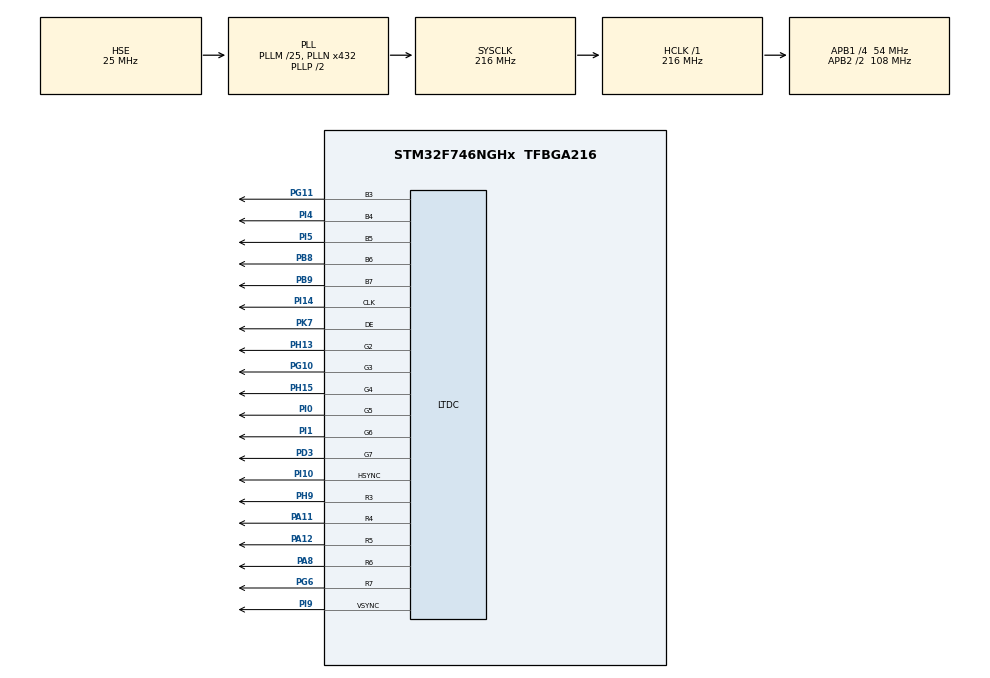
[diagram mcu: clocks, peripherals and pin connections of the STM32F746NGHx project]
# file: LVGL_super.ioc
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CORTEX_M7.default_mode_Activation=1
Mcu.Family=STM32F7
Mcu.Name=STM32F746NGHx
Mcu.Package=TFBGA216
NVIC.DMA2D_IRQn=true\:0\:0\:false\:false\:true\:true\:true\:true
NVIC.PriorityGroup=NVIC_PRIORITYGROUP_4
PA11.GPIO_Speed=GPIO_SPEED_FREQ_VERY_HIGH
PA11.Mode=RGB565
PA11.Signal=LTDC_R4
PA12.GPIO_Speed=GPIO_SPEED_FREQ_VERY_HIGH
PA12.Mode=RGB565
PA12.Signal=LTDC_R5
PA13.Mode=Serial_Wire
PA13.Signal=SYS_JTMS-SWDIO
PA14.Mode=Serial_Wire
PA14.Signal=SYS_JTCK-SWCLK
PA8.GPIO_Speed=GPIO_SPEED_FREQ_VERY_HIGH
PA8.Mode=RGB565
PA8.Signal=LTDC_R6
PB8.GPIO_Speed=GPIO_SPEED_FREQ_VERY_HIGH
PB8.Mode=RGB565
PB8.Signal=LTDC_B6
PB9.GPIO_Speed=GPIO_SPEED_FREQ_VERY_HIGH
PB9.Mode=RGB565
PB9.Signal=LTDC_B7
PD3.GPIO_Speed=GPIO_SPEED_FREQ_VERY_HIGH
PD3.Mode=RGB565
PD3.Signal=LTDC_G7
PG10.GPIO_Speed=GPIO_SPEED_FREQ_VERY_HIGH
PG10.Mode=RGB565
PG10.Signal=LTDC_G3
PG11.GPIO_Speed=GPIO_SPEED_FREQ_VERY_HIGH
PG11.Mode=RGB565
PG11.Signal=LTDC_B3
PG6.GPIO_Speed=GPIO_SPEED_FREQ_VERY_HIGH
PG6.Mode=RGB565
PG6.Signal=LTDC_R7
PH0/OSC_IN.Mode=HSE-External-Oscillator
PH0/OSC_IN.Signal=RCC_OSC_IN
PH1/OSC_OUT.Mode=HSE-External-Oscillator
PH1/OSC_OUT.Signal=RCC_OSC_OUT
PH13.GPIO_Speed=GPIO_SPEED_FREQ_VERY_HIGH
PH13.Mode=RGB565
PH13.Signal=LTDC_G2
PH15.GPIO_Speed=GPIO_SPEED_FREQ_VERY_HIGH
PH15.Mode=RGB565
PH15.Signal=LTDC_G4
PH9.GPIO_Speed=GPIO_SPEED_FREQ_VERY_HIGH
PH9.Mode=RGB565
PH9.Signal=LTDC_R3
PI0.GPIO_Speed=GPIO_SPEED_FREQ_VERY_HIGH
PI0.Mode=RGB565
PI0.Signal=LTDC_G5
PI1.GPIO_Speed=GPIO_SPEED_FREQ_VERY_HIGH
PI1.Mode=RGB565
PI1.Signal=LTDC_G6
PI10.GPIO_Speed=GPIO_SPEED_FREQ_VERY_HIGH
PI10.Mode=RGB565
PI10.Signal=LTDC_HSYNC
PI14.GPIO_Speed=GPIO_SPEED_FREQ_VERY_HIGH
PI14.Mode=RGB565
PI14.Signal=LTDC_CLK
PI4.GPIO_Speed=GPIO_SPEED_FREQ_VERY_HIGH
PI4.Mode=RGB565
PI4.Signal=LTDC_B4
PI5.GPIO_Speed=GPIO_SPEED_FREQ_VERY_HIGH
PI5.Mode=RGB565
PI5.Signal=LTDC_B5
PI9.GPIO_Speed=GPIO_SPEED_FREQ_VERY_HIGH
PI9.Mode=RGB565
PI9.Signal=LTDC_VSYNC
PK7.GPIO_Speed=GPIO_SPEED_FREQ_VERY_HIGH
PK7.Mode=RGB565
PK7.Signal=LTDC_DE
ProjectManager.HeapSize=0x200
ProjectManager.StackSize=0x400
ProjectManager.TargetToolchain=STM32CubeIDE
RCC.AHBFreq_Value=216000000
RCC.APB1CLKDivider=RCC_HCLK_DIV4
RCC.APB1Freq_Value=54000000
RCC.APB1TimFreq_Value=108000000
RCC.APB2CLKDivider=RCC_HCLK_DIV2
RCC.APB2Freq_Value=108000000
RCC.APB2TimFreq_Value=216000000
RCC.CortexFreq_Value=216000000
RCC.HCLKFreq_Value=216000000
RCC.HSE_VALUE=25000000
RCC.HSI_VALUE=16000000
RCC.LSE_VALUE=32768
RCC.PLLM=25
RCC.PLLN=432
RCC.PLLSAIN=180
RCC.PLLSourceVirtual=RCC_PLLSOURCE_HSE
RCC.SYSCLKFreq_VALUE=216000000
RCC.SYSCLKSource=RCC_SYSCLKSOURCE_PLLCLK
RCC.USBFreq_Value=216000000
RCC.VCOOutputFreq_Value=432000000
VP_DMA2D_VS_DMA2D.Mode=DMA2D_Activate
board=custom

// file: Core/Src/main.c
/* USER CODE BEGIN Header */
/**
  ******************************************************************************
  * @file           : main.c
  * @brief          : Main program body
  ******************************************************************************
  * @attention
  *
  * Copyright (c) 2025 STMicroelectronics.
  * All rights reserved.
  *
  * This software is licensed under terms that can be found in the LICENSE file
  * in the root directory of this software component.
  * If no LICENSE file comes with this software, it is provided AS-IS.
  *
  ******************************************************************************
  */
/* USER CODE END Header */
#include "main.h"

DMA2D_HandleTypeDef hdma2d;

LTDC_HandleTypeDef hltdc;

void SystemClock_Config(void);
static void MPU_Config(void);
static void MX_GPIO_Init(void);
static void MX_LTDC_Init(void);
static void MX_DMA2D_Init(void);

int main(void)
{

  /* MPU Configuration--------------------------------------------------------*/
  MPU_Config();

  /* MCU Configuration--------------------------------------------------------*/

  /* Reset of all peripherals, Initializes the Flash interface and the Systick. */
  HAL_Init();

  /* Configure the system clock */
  SystemClock_Config();

  /* Initialize all configured peripherals */
  MX_GPIO_Init();
  MX_LTDC_Init();
  MX_DMA2D_Init();
  /* USER CODE BEGIN 2 */
  lv_init();

  tft_init();
  touchpad_init();

  ui_init();
  /* USER CODE END 2 */

  /* Infinite loop */
  while (1)
  {

    /* USER CODE BEGIN 3 */
	  HAL_Delay(5);
	  lv_task_handler();
  }
  /* USER CODE END 3 */
}

void SystemClock_Config(void)
{
  RCC_OscInitTypeDef RCC_OscInitStruct = {0};
  RCC_ClkInitTypeDef RCC_ClkInitStruct = {0};

  /** Configure the main internal regulator output voltage
  */
  __HAL_RCC_PWR_CLK_ENABLE();
  __HAL_PWR_VOLTAGESCALING_CONFIG(PWR_REGULATOR_VOLTAGE_SCALE1);

  /** Initializes the RCC Oscillators according to the specified parameters
  * in the RCC_OscInitTypeDef structure.
  */
  RCC_OscInitStruct.OscillatorType = RCC_OSCILLATORTYPE_HSE;
  RCC_OscInitStruct.HSEState = RCC_HSE_ON;
  RCC_OscInitStruct.PLL.PLLState = RCC_PLL_ON;
  RCC_OscInitStruct.PLL.PLLSource = RCC_PLLSOURCE_HSE;
  RCC_OscInitStruct.PLL.PLLM = 25;
  RCC_OscInitStruct.PLL.PLLN = 432;
  RCC_OscInitStruct.PLL.PLLP = RCC_PLLP_DIV2;
  RCC_OscInitStruct.PLL.PLLQ = 2;
  if (HAL_RCC_OscConfig(&RCC_OscInitStruct) != HAL_OK)
  {
    Error_Handler();
  }

  /** Activate the Over-Drive mode
  */
  if (HAL_PWREx_EnableOverDrive() != HAL_OK)
  {
    Error_Handler();
  }

  /** Initializes the CPU, AHB and APB buses clocks
  */
  RCC_ClkInitStruct.ClockType = RCC_CLOCKTYPE_HCLK|RCC_CLOCKTYPE_SYSCLK
                              |RCC_CLOCKTYPE_PCLK1|RCC_CLOCKTYPE_PCLK2;
  RCC_ClkInitStruct.SYSCLKSource = RCC_SYSCLKSOURCE_PLLCLK;
  RCC_ClkInitStruct.AHBCLKDivider = RCC_SYSCLK_DIV1;
  RCC_ClkInitStruct.APB1CLKDivider = RCC_HCLK_DIV4;
  RCC_ClkInitStruct.APB2CLKDivider = RCC_HCLK_DIV2;

  if (HAL_RCC_ClockConfig(&RCC_ClkInitStruct, FLASH_LATENCY_7) != HAL_OK)
  {
    Error_Handler();
  }
}

static void MX_DMA2D_Init(void)
{

  hdma2d.Instance = DMA2D;
  hdma2d.Init.Mode = DMA2D_M2M;
  hdma2d.Init.ColorMode = DMA2D_OUTPUT_ARGB8888;
  hdma2d.Init.OutputOffset = 0;
  hdma2d.LayerCfg[1].InputOffset = 0;
  hdma2d.LayerCfg[1].InputColorMode = DMA2D_INPUT_ARGB8888;
  hdma2d.LayerCfg[1].AlphaMode = DMA2D_NO_MODIF_ALPHA;
  hdma2d.LayerCfg[1].InputAlpha = 0;
  if (HAL_DMA2D_Init(&hdma2d) != HAL_OK)
  {
    Error_Handler();
  }
  if (HAL_DMA2D_ConfigLayer(&hdma2d, 1) != HAL_OK)
  {
    Error_Handler();
  }

}

static void MX_LTDC_Init(void)
{

  LTDC_LayerCfgTypeDef pLayerCfg = {0};
  LTDC_LayerCfgTypeDef pLayerCfg1 = {0};

  hltdc.Instance = LTDC;
  hltdc.Init.HSPolarity = LTDC_HSPOLARITY_AL;
  hltdc.Init.VSPolarity = LTDC_VSPOLARITY_AL;
  hltdc.Init.DEPolarity = LTDC_DEPOLARITY_AL;
  hltdc.Init.PCPolarity = LTDC_PCPOLARITY_IPC;
  hltdc.Init.HorizontalSync = 7;
  hltdc.Init.VerticalSync = 3;
  hltdc.Init.AccumulatedHBP = 14;
  hltdc.Init.AccumulatedVBP = 5;
  hltdc.Init.AccumulatedActiveW = 654;
  hltdc.Init.AccumulatedActiveH = 485;
  hltdc.Init.TotalWidth = 660;
  hltdc.Init.TotalHeigh = 487;
  hltdc.Init.Backcolor.Blue = 0;
  hltdc.Init.Backcolor.Green = 0;
  hltdc.Init.Backcolor.Red = 0;
  if (HAL_LTDC_Init(&hltdc) != HAL_OK)
  {
    Error_Handler();
  }
  pLayerCfg.WindowX0 = 0;
  pLayerCfg.WindowX1 = 0;
  pLayerCfg.WindowY0 = 0;
  pLayerCfg.WindowY1 = 0;
  pLayerCfg.PixelFormat = LTDC_PIXEL_FORMAT_ARGB8888;
  pLayerCfg.Alpha = 0;
  pLayerCfg.Alpha0 = 0;
  pLayerCfg.BlendingFactor1 = LTDC_BLENDING_FACTOR1_CA;
  pLayerCfg.BlendingFactor2 = LTDC_BLENDING_FACTOR2_CA;
  pLayerCfg.FBStartAdress = 0;
  pLayerCfg.ImageWidth = 0;
  pLayerCfg.ImageHeight = 0;
  pLayerCfg.Backcolor.Blue = 0;
  pLayerCfg.Backcolor.Green = 0;
  pLayerCfg.Backcolor.Red = 0;
  if (HAL_LTDC_ConfigLayer(&hltdc, &pLayerCfg, 0) != HAL_OK)
  {
    Error_Handler();
  }
  pLayerCfg1.WindowX0 = 0;
  pLayerCfg1.WindowX1 = 0;
  pLayerCfg1.WindowY0 = 0;
  pLayerCfg1.WindowY1 = 0;
  pLayerCfg1.PixelFormat = LTDC_PIXEL_FORMAT_ARGB8888;
  pLayerCfg1.Alpha = 0;
  pLayerCfg1.Alpha0 = 0;
  pLayerCfg1.BlendingFactor1 = LTDC_BLENDING_FACTOR1_CA;
  pLayerCfg1.BlendingFactor2 = LTDC_BLENDING_FACTOR2_CA;
  pLayerCfg1.FBStartAdress = 0;
  pLayerCfg1.ImageWidth = 0;
  pLayerCfg1.ImageHeight = 0;
  pLayerCfg1.Backcolor.Blue = 0;
  pLayerCfg1.Backcolor.Green = 0;
  pLayerCfg1.Backcolor.Red = 0;
  if (HAL_LTDC_ConfigLayer(&hltdc, &pLayerCfg1, 1) != HAL_OK)
  {
    Error_Handler();
  }

}

static void MX_GPIO_Init(void)
{

  /* GPIO Ports Clock Enable */
  __HAL_RCC_GPIOB_CLK_ENABLE();
  __HAL_RCC_GPIOA_CLK_ENABLE();
  __HAL_RCC_GPIOG_CLK_ENABLE();
  __HAL_RCC_GPIOI_CLK_ENABLE();
  __HAL_RCC_GPIOK_CLK_ENABLE();
  __HAL_RCC_GPIOD_CLK_ENABLE();
  __HAL_RCC_GPIOH_CLK_ENABLE();

}

 /* MPU Configuration */

void MPU_Config(void)
{
  MPU_Region_InitTypeDef MPU_InitStruct = {0};

  /* Disables the MPU */
  HAL_MPU_Disable();

  /** Initializes and configures the Region and the memory to be protected
  */
  MPU_InitStruct.Enable = MPU_REGION_ENABLE;
  MPU_InitStruct.Number = MPU_REGION_NUMBER0;
  MPU_InitStruct.BaseAddress = 0x0;
  MPU_InitStruct.Size = MPU_REGION_SIZE_4GB;
  MPU_InitStruct.SubRegionDisable = 0x87;
  MPU_InitStruct.TypeExtField = MPU_TEX_LEVEL0;
  MPU_InitStruct.AccessPermission = MPU_REGION_NO_ACCESS;
  MPU_InitStruct.DisableExec = MPU_INSTRUCTION_ACCESS_DISABLE;
  MPU_InitStruct.IsShareable = MPU_ACCESS_SHAREABLE;
  MPU_InitStruct.IsCacheable = MPU_ACCESS_NOT_CACHEABLE;
  MPU_InitStruct.IsBufferable = MPU_ACCESS_NOT_BUFFERABLE;

  HAL_MPU_ConfigRegion(&MPU_InitStruct);
  /* Enables the MPU */
  HAL_MPU_Enable(MPU_PRIVILEGED_DEFAULT);

}

void Error_Handler(void)
{
  __disable_irq();
  while (1)
  {
  }
}
